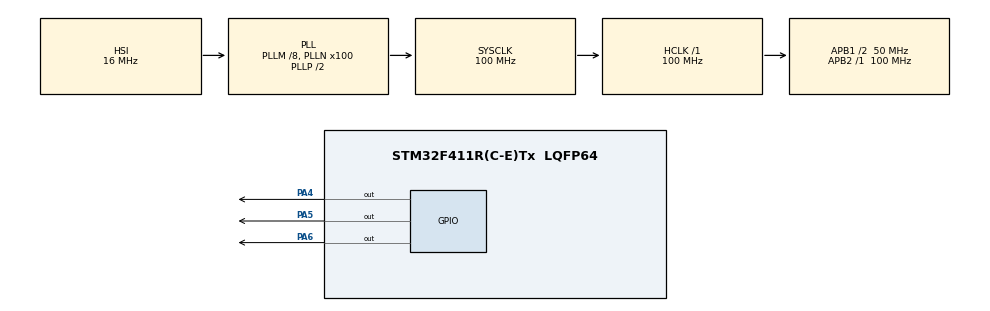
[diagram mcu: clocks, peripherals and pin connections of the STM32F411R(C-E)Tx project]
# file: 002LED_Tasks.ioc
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Mcu.Family=STM32F4
RCC.CortexFreq_Value=100000000
VP_SYS_VS_tim5.Mode=TIM5
RCC.APB1CLKDivider=RCC_HCLK_DIV2
RCC.SYSCLKSource=RCC_SYSCLKSOURCE_PLLCLK
ProjectManager.StackSize=0x400
ProjectManager.TargetToolchain=STM32CubeIDE
NVIC.TIM5_IRQn=true\:0\:0\:false\:false\:true\:false\:true
RCC.HCLKFreq_Value=100000000
RCC.APB2TimFreq_Value=100000000
RCC.LSE_VALUE=32768
RCC.AHBFreq_Value=100000000
PA5.Signal=GPIO_Output
RCC.HSE_VALUE=25000000
board=custom
RCC.VCOOutputFreq_Value=200000000
RCC.APB2Freq_Value=100000000
Mcu.Name=STM32F411R(C-E)Tx
RCC.48MHZClocksFreq_Value=50000000
PA4.Signal=GPIO_Output
RCC.SYSCLKFreq_VALUE=100000000
Mcu.Package=LQFP64
PA6.Signal=GPIO_Output
NVIC.TimeBase=TIM5_IRQn
NVIC.TimeBaseIP=TIM5
ProjectManager.HeapSize=0x200
RCC.HSI_VALUE=16000000
NVIC.PriorityGroup=NVIC_PRIORITYGROUP_4
RCC.PLLM=8
RCC.PLLN=100
RCC.APB1TimFreq_Value=100000000
RCC.APB1Freq_Value=50000000

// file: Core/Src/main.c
/* USER CODE BEGIN Header */
/**
  ******************************************************************************
  * @file           : main.c
  * @brief          : Main program body
  ******************************************************************************
  * @attention
  *
  * <h2><center>&copy; Copyright (c) 2022 STMicroelectronics.
  * All rights reserved.</center></h2>
  *
  * This software component is licensed by ST under BSD 3-Clause license,
  * the "License"; You may not use this file except in compliance with the
  * License. You may obtain a copy of the License at:
  *                        opensource.org/licenses/BSD-3-Clause
  *
  ******************************************************************************
  */
/* USER CODE END Header */
#include "main.h"

/* USER CODE BEGIN Includes */
#include "FreeRTOS.h"
#include "task.h"
#include <stdio.h>
/* USER CODE END Includes */

/* USER CODE BEGIN PV */
#define DWT_CTRL (*(volatile uint32_t* ) 0XE0001000)
/* USER CODE END PV */

void SystemClock_Config(void);
static void MX_GPIO_Init(void);
/* USER CODE BEGIN PFP */
static void task1_handler(void *parameters);
static void task2_handler(void *parameters);
static void task3_handler(void *parameters);
/* USER CODE END PFP */

int main(void)
{
  /* USER CODE BEGIN 1 */
	TaskHandle_t task1_handle;
	TaskHandle_t task2_handle;
	TaskHandle_t task3_handle;\

	BaseType_t status;
  /* USER CODE END 1 */

  /* MCU Configuration--------------------------------------------------------*/

  /* Reset of all peripherals, Initializes the Flash interface and the Systick. */
  HAL_Init();

  /* Configure the system clock */
  SystemClock_Config();

  /* Initialize all configured peripherals */
  MX_GPIO_Init();
  /* USER CODE BEGIN 2 */
  // Enable the CYCCNT counter
   DWT_CTRL |=(1<<0);
   SEGGER_SYSVIEW_Conf();
   SEGGER_SYSVIEW_Start();
   status = xTaskCreate(task1_handler, "Task1", 200, "Toggle LED from Task1", 2, &task1_handle);
   configASSERT(status == pdPASS);

   status = xTaskCreate(task2_handler, "Task2", 200, "Toggle Buzzer from Task2", 2, &task2_handle);
   configASSERT(status == pdPASS);

   status = xTaskCreate(task3_handler, "Task3", 200, "Toggle LED from Task3", 2, &task3_handle);
   configASSERT(status == pdPASS);
   //start scheduler
   vTaskStartScheduler();
  /* USER CODE END 2 */

  /* Infinite loop */
  while (1)
  {

  }
}

void SystemClock_Config(void)
{
  RCC_OscInitTypeDef RCC_OscInitStruct = {0};
  RCC_ClkInitTypeDef RCC_ClkInitStruct = {0};

  /** Configure the main internal regulator output voltage
  */
  __HAL_RCC_PWR_CLK_ENABLE();
  __HAL_PWR_VOLTAGESCALING_CONFIG(PWR_REGULATOR_VOLTAGE_SCALE1);
  /** Initializes the RCC Oscillators according to the specified parameters
  * in the RCC_OscInitTypeDef structure.
  */
  RCC_OscInitStruct.OscillatorType = RCC_OSCILLATORTYPE_HSI;
  RCC_OscInitStruct.HSIState = RCC_HSI_ON;
  RCC_OscInitStruct.HSICalibrationValue = RCC_HSICALIBRATION_DEFAULT;
  RCC_OscInitStruct.PLL.PLLState = RCC_PLL_ON;
  RCC_OscInitStruct.PLL.PLLSource = RCC_PLLSOURCE_HSI;
  RCC_OscInitStruct.PLL.PLLM = 8;
  RCC_OscInitStruct.PLL.PLLN = 100;
  RCC_OscInitStruct.PLL.PLLP = RCC_PLLP_DIV2;
  RCC_OscInitStruct.PLL.PLLQ = 4;
  if (HAL_RCC_OscConfig(&RCC_OscInitStruct) != HAL_OK)
  {
    Error_Handler();
  }
  /** Initializes the CPU, AHB and APB buses clocks
  */
  RCC_ClkInitStruct.ClockType = RCC_CLOCKTYPE_HCLK|RCC_CLOCKTYPE_SYSCLK
                              |RCC_CLOCKTYPE_PCLK1|RCC_CLOCKTYPE_PCLK2;
  RCC_ClkInitStruct.SYSCLKSource = RCC_SYSCLKSOURCE_PLLCLK;
  RCC_ClkInitStruct.AHBCLKDivider = RCC_SYSCLK_DIV1;
  RCC_ClkInitStruct.APB1CLKDivider = RCC_HCLK_DIV2;
  RCC_ClkInitStruct.APB2CLKDivider = RCC_HCLK_DIV1;

  if (HAL_RCC_ClockConfig(&RCC_ClkInitStruct, FLASH_LATENCY_3) != HAL_OK)
  {
    Error_Handler();
  }
}

static void MX_GPIO_Init(void)
{
  GPIO_InitTypeDef GPIO_InitStruct = {0};

  /* GPIO Ports Clock Enable */
  __HAL_RCC_GPIOA_CLK_ENABLE();

  /*Configure GPIO pin Output Level */
  HAL_GPIO_WritePin(GPIOA, GPIO_PIN_4|GPIO_PIN_5|GPIO_PIN_6, GPIO_PIN_RESET);

  /*Configure GPIO pins : PA4 PA5 PA6 */
  GPIO_InitStruct.Pin = GPIO_PIN_4|GPIO_PIN_5|GPIO_PIN_6;
  GPIO_InitStruct.Mode = GPIO_MODE_OUTPUT_PP;
  GPIO_InitStruct.Pull = GPIO_NOPULL;
  GPIO_InitStruct.Speed = GPIO_SPEED_FREQ_LOW;
  HAL_GPIO_Init(GPIOA, &GPIO_InitStruct);

}

/* USER CODE BEGIN 4 */
static void task1_handler(void *parameters){
	while(1){
		HAL_GPIO_TogglePin(GPIOA, GPIO_PIN_4);
		HAL_Delay(1000);
	}
}
static void task2_handler(void *parameters){
	while(1){
		HAL_GPIO_TogglePin(GPIOA, GPIO_PIN_5);
		HAL_Delay(800);
	}
}
static void task3_handler(void *parameters){
	while(1){
		HAL_GPIO_TogglePin(GPIOA, GPIO_PIN_6);
		HAL_Delay(200);
	}
}
/* USER CODE END 4 */

 /**
  * @brief  Period elapsed callback in non blocking mode
  * @note   This function is called  when TIM5 interrupt took place, inside
  * HAL_TIM_IRQHandler(). It makes a direct call to HAL_IncTick() to increment
  * a global variable "uwTick" used as application time base.
  * @param  htim : TIM handle
  * @retval None
  */
void HAL_TIM_PeriodElapsedCallback(TIM_HandleTypeDef *htim)
{
  if (htim->Instance == TIM5) {
    HAL_IncTick();
  }
}

void Error_Handler(void)
{
  __disable_irq();
  while (1)
  {
  }
}

/************************ (C) COPYRIGHT STMicroelectronics *****END OF FILE****/
